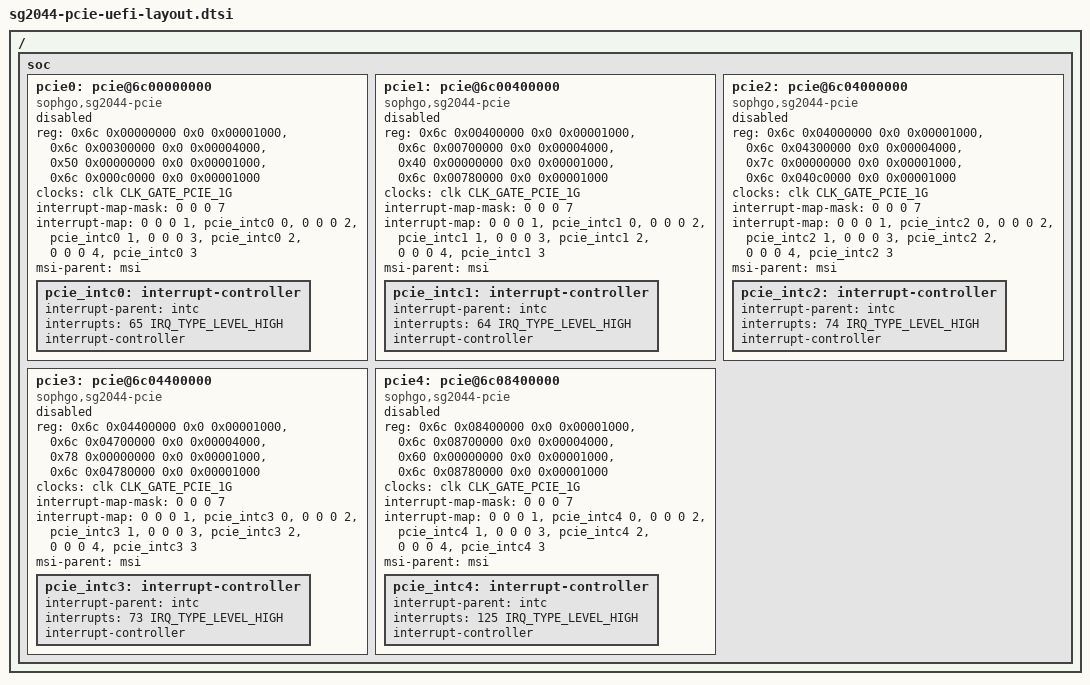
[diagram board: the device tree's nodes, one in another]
// SPDX-License-Identifier: (GPL-2.0 OR MIT)
/*
 * Copyright (C) 2026 Inochi Amaoto <inochiama@gmail.com>
 */

/ {
	soc {
		pcie0: pcie@6c00000000 {
			compatible = "sophgo,sg2044-pcie";
			reg = <0x6c 0x00000000 0x0 0x00001000>,
			      <0x6c 0x00300000 0x0 0x00004000>,
			      <0x50 0x00000000 0x0 0x00001000>,
			      <0x6c 0x000c0000 0x0 0x00001000>;
			reg-names = "dbi", "atu", "config", "app";
			#address-cells = <3>;
			#size-cells = <2>;
			#interrupt-cells = <1>;
			clocks = <&clk CLK_GATE_PCIE_1G>;
			clock-names = "core";
			device_type = "pci";
			interrupt-map-mask = <0 0 0 7>;
			interrupt-map = <0 0 0 1 &pcie_intc0 0>,
					<0 0 0 2 &pcie_intc0 1>,
					<0 0 0 3 &pcie_intc0 2>,
					<0 0 0 4 &pcie_intc0 3>;
			msi-parent = <&msi>;
			ranges = <0x01000000 0x0  0x00000000  0x50 0x10000000  0x0 0x00100000>,
				 <0x02000000 0x0  0x50000000  0x0  0x50000000  0x0 0x10000000>,
				 <0x43000000 0x58 0x00000000  0x58 0x00000000  0x8 0x00000000>;
			status = "disabled";

			pcie_intc0: interrupt-controller {
				#address-cells = <0>;
				#interrupt-cells = <1>;
				interrupt-parent = <&intc>;
				interrupts = <65 IRQ_TYPE_LEVEL_HIGH>;
				interrupt-controller;
			};
		};

		pcie1: pcie@6c00400000 {
			compatible = "sophgo,sg2044-pcie";
			reg = <0x6c 0x00400000 0x0 0x00001000>,
			      <0x6c 0x00700000 0x0 0x00004000>,
			      <0x40 0x00000000 0x0 0x00001000>,
			      <0x6c 0x00780000 0x0 0x00001000>;
			reg-names = "dbi", "atu", "config", "app";
			#address-cells = <3>;
			#size-cells = <2>;
			#interrupt-cells = <1>;
			clocks = <&clk CLK_GATE_PCIE_1G>;
			clock-names = "core";
			device_type = "pci";
			interrupt-map-mask = <0 0 0 7>;
			interrupt-map = <0 0 0 1 &pcie_intc1 0>,
					<0 0 0 2 &pcie_intc1 1>,
					<0 0 0 3 &pcie_intc1 2>,
					<0 0 0 4 &pcie_intc1 3>;
			msi-parent = <&msi>;
			ranges = <0x01000000 0x0  0x00000000  0x40 0x10000000  0x0 0x00100000>,
				 <0x02000000 0x0  0x40000000  0x0  0x40000000  0x0 0x10000000>,
				 <0x43000000 0x48 0x00000000  0x48 0x00000000  0x8 0x00000000>;
			status = "disabled";

			pcie_intc1: interrupt-controller {
				#address-cells = <0>;
				#interrupt-cells = <1>;
				interrupt-parent = <&intc>;
				interrupts = <64 IRQ_TYPE_LEVEL_HIGH>;
				interrupt-controller;
			};
		};

		pcie2: pcie@6c04000000 {
			compatible = "sophgo,sg2044-pcie";
			reg = <0x6c 0x04000000 0x0 0x00001000>,
			      <0x6c 0x04300000 0x0 0x00004000>,
			      <0x7c 0x00000000 0x0 0x00001000>,
			      <0x6c 0x040c0000 0x0 0x00001000>;
			reg-names = "dbi", "atu", "config", "app";
			#address-cells = <3>;
			#size-cells = <2>;
			#interrupt-cells = <1>;
			clocks = <&clk CLK_GATE_PCIE_1G>;
			clock-names = "core";
			device_type = "pci";
			interrupt-map-mask = <0 0 0 7>;
			interrupt-map = <0 0 0 1 &pcie_intc2 0>,
					<0 0 0 2 &pcie_intc2 1>,
					<0 0 0 3 &pcie_intc2 2>,
					<0 0 0 4 &pcie_intc2 3>;
			msi-parent = <&msi>;
			ranges = <0x01000000 0x0  0x00000000  0x7c 0x10000000  0x0 0x00100000>,
				 <0x02000000 0x0  0x30000000  0x0  0x30000000  0x0 0x10000000>,
				 <0x43000000 0x7e 0x00000000  0x7e 0x00000000  0x2 0x00000000>;
			status = "disabled";

			pcie_intc2: interrupt-controller {
				#address-cells = <0>;
				#interrupt-cells = <1>;
				interrupt-parent = <&intc>;
				interrupts = <74 IRQ_TYPE_LEVEL_HIGH>;
				interrupt-controller;
			};
		};

		pcie3: pcie@6c04400000 {
			compatible = "sophgo,sg2044-pcie";
			reg = <0x6c 0x04400000 0x0 0x00001000>,
			      <0x6c 0x04700000 0x0 0x00004000>,
			      <0x78 0x00000000 0x0 0x00001000>,
			      <0x6c 0x04780000 0x0 0x00001000>;
			reg-names = "dbi", "atu", "config", "app";
			#address-cells = <3>;
			#size-cells = <2>;
			#interrupt-cells = <1>;
			clocks = <&clk CLK_GATE_PCIE_1G>;
			clock-names = "core";
			device_type = "pci";
			interrupt-map-mask = <0 0 0 7>;
			interrupt-map = <0 0 0 1 &pcie_intc3 0>,
					<0 0 0 2 &pcie_intc3 1>,
					<0 0 0 3 &pcie_intc3 2>,
					<0 0 0 4 &pcie_intc3 3>;
			msi-parent = <&msi>;
			ranges = <0x01000000 0x0  0x00000000  0x78 0x10000000  0x0 0x00100000>,
				 <0x02000000 0x0  0x20000000  0x0  0x20000000  0x0 0x10000000>,
				 <0x43000000 0x7a 0x00000000  0x7a 0x00000000  0x2 0x00000000>;
			status = "disabled";

			pcie_intc3: interrupt-controller {
				#address-cells = <0>;
				#interrupt-cells = <1>;
				interrupt-parent = <&intc>;
				interrupts = <73 IRQ_TYPE_LEVEL_HIGH>;
				interrupt-controller;
			};
		};

		pcie4: pcie@6c08400000 {
			compatible = "sophgo,sg2044-pcie";
			reg = <0x6c 0x08400000 0x0 0x00001000>,
			      <0x6c 0x08700000 0x0 0x00004000>,
			      <0x60 0x00000000 0x0 0x00001000>,
			      <0x6c 0x08780000 0x0 0x00001000>;
			reg-names = "dbi", "atu", "config", "app";
			#address-cells = <3>;
			#size-cells = <2>;
			#interrupt-cells = <1>;
			clocks = <&clk CLK_GATE_PCIE_1G>;
			clock-names = "core";
			device_type = "pci";
			interrupt-map-mask = <0 0 0 7>;
			interrupt-map = <0 0 0 1 &pcie_intc4 0>,
					<0 0 0 2 &pcie_intc4 1>,
					<0 0 0 3 &pcie_intc4 2>,
					<0 0 0 4 &pcie_intc4 3>;
			msi-parent = <&msi>;
			ranges = <0x01000000 0x0  0x00000000  0x60 0x10000000  0x0 0x00100000>,
				 <0x02000000 0x0  0x10000000  0x0  0x10000000  0x0 0x10000000>,
				 <0x43000000 0x64 0x00000000  0x64 0x00000000  0x4 0x00000000>;
			status = "disabled";

			pcie_intc4: interrupt-controller {
				#address-cells = <0>;
				#interrupt-cells = <1>;
				interrupt-parent = <&intc>;
				interrupts = <125 IRQ_TYPE_LEVEL_HIGH>;
				interrupt-controller;
			};
		};
	};
};
